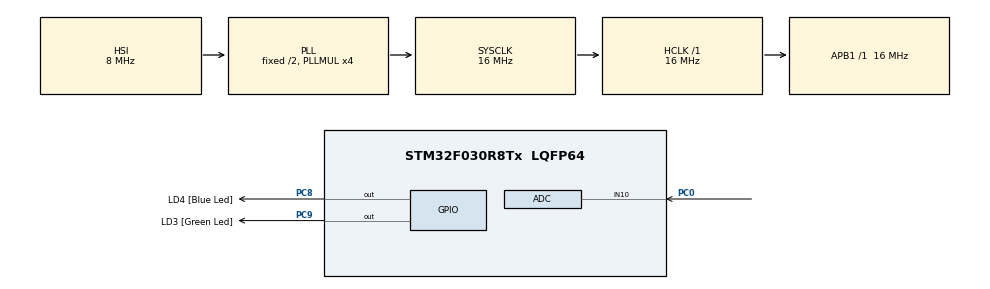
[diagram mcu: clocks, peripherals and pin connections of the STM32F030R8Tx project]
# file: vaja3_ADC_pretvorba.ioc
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ADC.ClockPrescaler=ADC_CLOCK_ASYNC_DIV1
ADC.ContinuousConvMode=DISABLE
ADC.DMAContinuousRequests=DISABLE
ADC.DataAlign=ADC_DATAALIGN_RIGHT
ADC.DiscontinuousConvMode=DISABLE
ADC.EOCSelection=ADC_EOC_SINGLE_CONV
ADC.EnableAnalogWatchDog=false
ADC.ExternalTrigConv=ADC_EXTERNALTRIGCONV_T1_TRGO
ADC.ExternalTrigConvEdge=ADC_EXTERNALTRIGCONVEDGE_RISING
ADC.LowPowerAutoPowerOff=DISABLE
ADC.LowPowerAutoWait=DISABLE
ADC.Overrun=ADC_OVR_DATA_PRESERVED
ADC.Resolution=ADC_RESOLUTION_8B
ADC.SamplingTime=ADC_SAMPLETIME_28CYCLES_5
ADC.ScanConvMode=ADC_SCAN_DIRECTION_FORWARD
Mcu.Family=STM32F0
Mcu.Name=STM32F030R8Tx
Mcu.Package=LQFP64
NVIC.ADC1_IRQn=true\:0\:0\:false\:false\:true\:true
PA13.GPIO_Label=SWDIO
PA13.Mode=Serial_Wire
PA13.Signal=SYS_SWDIO
PA14.GPIO_Label=SWCLK
PA14.Mode=Serial_Wire
PA14.Signal=SYS_SWCLK
PC0.Mode=IN10
PC0.Signal=ADC_IN10
PC8.GPIO_Label=LD4 [Blue Led]
PC8.Signal=GPIO_Output
PC9.GPIO_Label=LD3 [Green Led]
PC9.Signal=GPIO_Output
ProjectManager.HeapSize=0x200
ProjectManager.StackSize=0x400
ProjectManager.TargetToolchain=MDK-ARM V5
RCC.AHBFreq_Value=16000000
RCC.APB1Freq_Value=16000000
RCC.APB1TimFreq_Value=16000000
RCC.HCLKFreq_Value=16000000
RCC.PLLMUL=RCC_PLL_MUL4
RCC.SYSCLKFreq_VALUE=16000000
RCC.SYSCLKSource=RCC_SYSCLKSOURCE_PLLCLK
TIM1.Period=100
TIM1.Prescaler=16000
TIM1.TIM_MasterOutputTrigger=TIM_TRGO_UPDATE
VP_TIM1_VS_ClockSourceINT.Mode=Internal
board=32F0308DISCOVERY

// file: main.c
/**
  ******************************************************************************
  * @file           : main.c
  * @brief          : Main program body
  ******************************************************************************
  ** This notice applies to any and all portions of this file
  * that are not between comment pairs USER CODE BEGIN and
  * USER CODE END. Other portions of this file, whether
  * inserted by the user or by software development tools
  * are owned by their respective copyright owners.
  *
  * COPYRIGHT(c) 2019 STMicroelectronics
  *
  * Redistribution and use in source and binary forms, with or without modification,
  * are permitted provided that the following conditions are met:
  *   1. Redistributions of source code must retain the above copyright notice,
  *      this list of conditions and the following disclaimer.
  *   2. Redistributions in binary form must reproduce the above copyright notice,
  *      this list of conditions and the following disclaimer in the documentation
  *      and/or other materials provided with the distribution.
  *   3. Neither the name of STMicroelectronics nor the names of its contributors
  *      may be used to endorse or promote products derived from this software
  *      without specific prior written permission.
  *
  * THIS SOFTWARE IS PROVIDED BY THE COPYRIGHT HOLDERS AND CONTRIBUTORS "AS IS"
  * AND ANY EXPRESS OR IMPLIED WARRANTIES, INCLUDING, BUT NOT LIMITED TO, THE
  * IMPLIED WARRANTIES OF MERCHANTABILITY AND FITNESS FOR A PARTICULAR PURPOSE ARE
  * DISCLAIMED. IN NO EVENT SHALL THE COPYRIGHT HOLDER OR CONTRIBUTORS BE LIABLE
  * FOR ANY DIRECT, INDIRECT, INCIDENTAL, SPECIAL, EXEMPLARY, OR CONSEQUENTIAL
  * DAMAGES (INCLUDING, BUT NOT LIMITED TO, PROCUREMENT OF SUBSTITUTE GOODS OR
  * SERVICES; LOSS OF USE, DATA, OR PROFITS; OR BUSINESS INTERRUPTION) HOWEVER
  * CAUSED AND ON ANY THEORY OF LIABILITY, WHETHER IN CONTRACT, STRICT LIABILITY,
  * OR TORT (INCLUDING NEGLIGENCE OR OTHERWISE) ARISING IN ANY WAY OUT OF THE USE
  * OF THIS SOFTWARE, EVEN IF ADVISED OF THE POSSIBILITY OF SUCH DAMAGE.
  *
  ******************************************************************************
  */
#include "main.h"
#include "stm32f0xx_hal.h"

ADC_HandleTypeDef hadc;

TIM_HandleTypeDef htim1;

/* USER CODE BEGIN PV */
/* Private variables ---------------------------------------------------------*/

/* USER CODE END PV */

void SystemClock_Config(void);
static void MX_GPIO_Init(void);
static void MX_ADC_Init(void);
static void MX_TIM1_Init(void);

/* USER CODE BEGIN PFP */
/* Private function prototypes -----------------------------------------------*/

/* USER CODE END PFP */

/* USER CODE BEGIN 0 */
uint8_t adcVal;

/* USER CODE END 0 */

int main(void)
{

  /* MCU Configuration----------------------------------------------------------*/

  /* Reset of all peripherals, Initializes the Flash interface and the Systick. */
  HAL_Init();

  /* Configure the system clock */
  SystemClock_Config();

  /* Initialize all configured peripherals */
  MX_GPIO_Init();
  MX_ADC_Init();
  MX_TIM1_Init();
  /* USER CODE BEGIN 2 */
	HAL_ADC_Start_IT(&hadc);
  HAL_TIM_Base_Start(&htim1);

  /* USER CODE END 2 */

  /* Infinite loop */
  while (1)
  {

  }

}

void SystemClock_Config(void)
{

  RCC_OscInitTypeDef RCC_OscInitStruct;
  RCC_ClkInitTypeDef RCC_ClkInitStruct;

    /**Initializes the CPU, AHB and APB busses clocks
    */
  RCC_OscInitStruct.OscillatorType = RCC_OSCILLATORTYPE_HSI|RCC_OSCILLATORTYPE_HSI14;
  RCC_OscInitStruct.HSIState = RCC_HSI_ON;
  RCC_OscInitStruct.HSI14State = RCC_HSI14_ON;
  RCC_OscInitStruct.HSICalibrationValue = 16;
  RCC_OscInitStruct.HSI14CalibrationValue = 16;
  RCC_OscInitStruct.PLL.PLLState = RCC_PLL_ON;
  RCC_OscInitStruct.PLL.PLLSource = RCC_PLLSOURCE_HSI;
  RCC_OscInitStruct.PLL.PLLMUL = RCC_PLL_MUL4;
  RCC_OscInitStruct.PLL.PREDIV = RCC_PREDIV_DIV1;
  if (HAL_RCC_OscConfig(&RCC_OscInitStruct) != HAL_OK)
  {
    _Error_Handler(__FILE__, __LINE__);
  }

    /**Initializes the CPU, AHB and APB busses clocks
    */
  RCC_ClkInitStruct.ClockType = RCC_CLOCKTYPE_HCLK|RCC_CLOCKTYPE_SYSCLK
                              |RCC_CLOCKTYPE_PCLK1;
  RCC_ClkInitStruct.SYSCLKSource = RCC_SYSCLKSOURCE_PLLCLK;
  RCC_ClkInitStruct.AHBCLKDivider = RCC_SYSCLK_DIV1;
  RCC_ClkInitStruct.APB1CLKDivider = RCC_HCLK_DIV1;

  if (HAL_RCC_ClockConfig(&RCC_ClkInitStruct, FLASH_LATENCY_0) != HAL_OK)
  {
    _Error_Handler(__FILE__, __LINE__);
  }

    /**Configure the Systick interrupt time
    */
  HAL_SYSTICK_Config(HAL_RCC_GetHCLKFreq()/1000);

    /**Configure the Systick
    */
  HAL_SYSTICK_CLKSourceConfig(SYSTICK_CLKSOURCE_HCLK);

  /* SysTick_IRQn interrupt configuration */
  HAL_NVIC_SetPriority(SysTick_IRQn, 0, 0);
}

/* ADC init function */
static void MX_ADC_Init(void)
{

  ADC_ChannelConfTypeDef sConfig;

    /**Configure the global features of the ADC (Clock, Resolution, Data Alignment and number of conversion)
    */
  hadc.Instance = ADC1;
  hadc.Init.ClockPrescaler = ADC_CLOCK_ASYNC_DIV1;
  hadc.Init.Resolution = ADC_RESOLUTION_8B;
  hadc.Init.DataAlign = ADC_DATAALIGN_RIGHT;
  hadc.Init.ScanConvMode = ADC_SCAN_DIRECTION_FORWARD;
  hadc.Init.EOCSelection = ADC_EOC_SINGLE_CONV;
  hadc.Init.LowPowerAutoWait = DISABLE;
  hadc.Init.LowPowerAutoPowerOff = DISABLE;
  hadc.Init.ContinuousConvMode = DISABLE;
  hadc.Init.DiscontinuousConvMode = DISABLE;
  hadc.Init.ExternalTrigConv = ADC_EXTERNALTRIGCONV_T1_TRGO;
  hadc.Init.ExternalTrigConvEdge = ADC_EXTERNALTRIGCONVEDGE_RISING;
  hadc.Init.DMAContinuousRequests = DISABLE;
  hadc.Init.Overrun = ADC_OVR_DATA_PRESERVED;
  if (HAL_ADC_Init(&hadc) != HAL_OK)
  {
    _Error_Handler(__FILE__, __LINE__);
  }

    /**Configure for the selected ADC regular channel to be converted.
    */
  sConfig.Channel = ADC_CHANNEL_10;
  sConfig.Rank = ADC_RANK_CHANNEL_NUMBER;
  sConfig.SamplingTime = ADC_SAMPLETIME_28CYCLES_5;
  if (HAL_ADC_ConfigChannel(&hadc, &sConfig) != HAL_OK)
  {
    _Error_Handler(__FILE__, __LINE__);
  }

}

/* TIM1 init function */
static void MX_TIM1_Init(void)
{

  TIM_ClockConfigTypeDef sClockSourceConfig;
  TIM_MasterConfigTypeDef sMasterConfig;

  htim1.Instance = TIM1;
  htim1.Init.Prescaler = 16000;
  htim1.Init.CounterMode = TIM_COUNTERMODE_UP;
  htim1.Init.Period = 100;
  htim1.Init.ClockDivision = TIM_CLOCKDIVISION_DIV1;
  htim1.Init.RepetitionCounter = 0;
  htim1.Init.AutoReloadPreload = TIM_AUTORELOAD_PRELOAD_DISABLE;
  if (HAL_TIM_Base_Init(&htim1) != HAL_OK)
  {
    _Error_Handler(__FILE__, __LINE__);
  }

  sClockSourceConfig.ClockSource = TIM_CLOCKSOURCE_INTERNAL;
  if (HAL_TIM_ConfigClockSource(&htim1, &sClockSourceConfig) != HAL_OK)
  {
    _Error_Handler(__FILE__, __LINE__);
  }

  sMasterConfig.MasterOutputTrigger = TIM_TRGO_UPDATE;
  sMasterConfig.MasterSlaveMode = TIM_MASTERSLAVEMODE_DISABLE;
  if (HAL_TIMEx_MasterConfigSynchronization(&htim1, &sMasterConfig) != HAL_OK)
  {
    _Error_Handler(__FILE__, __LINE__);
  }

}

/** Configure pins as
        * Analog
        * Input
        * Output
        * EVENT_OUT
        * EXTI
*/
static void MX_GPIO_Init(void)
{

  GPIO_InitTypeDef GPIO_InitStruct;

  /* GPIO Ports Clock Enable */
  __HAL_RCC_GPIOC_CLK_ENABLE();
  __HAL_RCC_GPIOA_CLK_ENABLE();

  /*Configure GPIO pin Output Level */
  HAL_GPIO_WritePin(GPIOC, LD4_Pin|LD3_Pin, GPIO_PIN_RESET);

  /*Configure GPIO pins : LD4_Pin LD3_Pin */
  GPIO_InitStruct.Pin = LD4_Pin|LD3_Pin;
  GPIO_InitStruct.Mode = GPIO_MODE_OUTPUT_PP;
  GPIO_InitStruct.Pull = GPIO_NOPULL;
  GPIO_InitStruct.Speed = GPIO_SPEED_FREQ_LOW;
  HAL_GPIO_Init(GPIOC, &GPIO_InitStruct);

}

/* USER CODE BEGIN 4 */
void HAL_ADC_ConvCpltCallback(ADC_HandleTypeDef* hadc)
{
	UNUSED(hadc);
	adcVal = HAL_ADC_GetValue(hadc);
	HAL_GPIO_TogglePin(GPIOC, GPIO_PIN_9);
}
/* USER CODE END 4 */

void _Error_Handler(char *file, int line)
{
  while(1)
  {
  }
}

/************************ (C) COPYRIGHT STMicroelectronics *****END OF FILE****/
